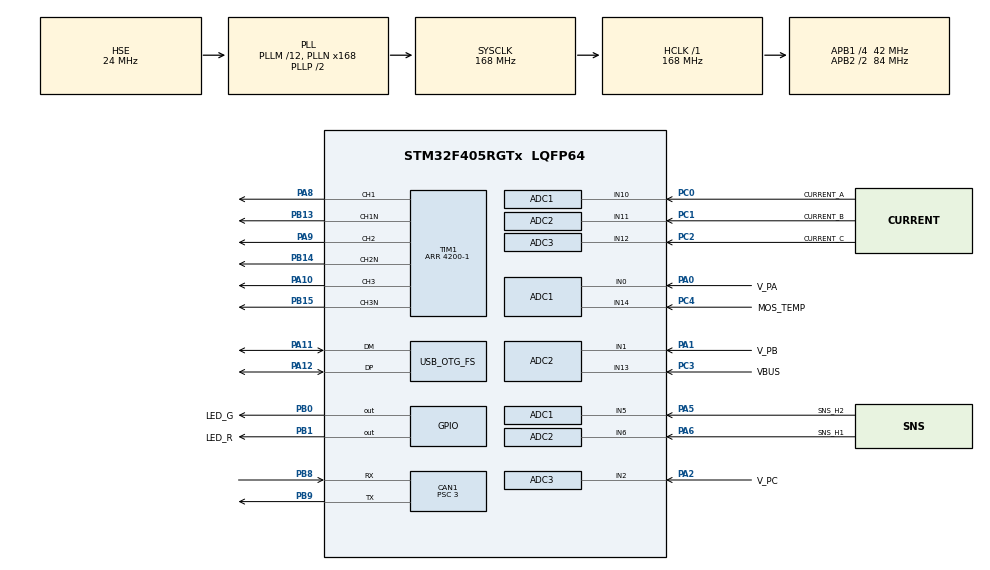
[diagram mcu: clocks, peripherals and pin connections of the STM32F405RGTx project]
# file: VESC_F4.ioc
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ADC1.Channel-0\#ChannelRegularConversion=ADC_CHANNEL_14
ADC1.Channel-1\#ChannelInjectedConversion=ADC_CHANNEL_10
ADC1.Channel-5\#ChannelInjectedConversion=ADC_CHANNEL_0
ADC1.Channel-6\#ChannelInjectedConversion=ADC_CHANNEL_5
ADC1.ClockPrescaler=ADC_CLOCK_SYNC_PCLK_DIV4
ADC1.ExternalTrigConv=ADC_EXTERNALTRIGCONV_T2_TRGO
ADC1.ExternalTrigInjecConv=ADC_EXTERNALTRIGINJECCONV_T1_TRGO
ADC1.InjNumberOfConversion=3
ADC1.InjectedOffset-1\#ChannelInjectedConversion=0
ADC1.InjectedOffset-5\#ChannelInjectedConversion=0
ADC1.InjectedOffset-6\#ChannelInjectedConversion=0
ADC1.InjectedRank-1\#ChannelInjectedConversion=1
ADC1.InjectedRank-5\#ChannelInjectedConversion=2
ADC1.InjectedRank-6\#ChannelInjectedConversion=3
ADC1.NbrOfConversion=1
ADC1.NbrOfConversionFlag=1
ADC1.Rank-0\#ChannelRegularConversion=1
ADC1.SamplingTime-0\#ChannelRegularConversion=ADC_SAMPLETIME_480CYCLES
ADC1.SamplingTime-1\#ChannelInjectedConversion=ADC_SAMPLETIME_15CYCLES
ADC1.SamplingTime-5\#ChannelInjectedConversion=ADC_SAMPLETIME_112CYCLES
ADC1.SamplingTime-6\#ChannelInjectedConversion=ADC_SAMPLETIME_28CYCLES
ADC1.master=1
ADC2.Channel-0\#ChannelRegularConversion=ADC_CHANNEL_13
ADC2.Channel-1\#ChannelInjectedConversion=ADC_CHANNEL_11
ADC2.Channel-4\#ChannelInjectedConversion=ADC_CHANNEL_1
ADC2.Channel-5\#ChannelInjectedConversion=ADC_CHANNEL_6
ADC2.ClockPrescaler=ADC_CLOCK_SYNC_PCLK_DIV4
ADC2.EnableAnalogWatchDog=false
ADC2.ExternalTrigConv=ADC_EXTERNALTRIGCONV_T2_TRGO
ADC2.ExternalTrigInjecConv=ADC_EXTERNALTRIGINJECCONV_T1_TRGO
ADC2.InjNumberOfConversion=3
ADC2.InjectedOffset-1\#ChannelInjectedConversion=0
ADC2.InjectedOffset-4\#ChannelInjectedConversion=0
ADC2.InjectedOffset-5\#ChannelInjectedConversion=0
ADC2.InjectedRank-1\#ChannelInjectedConversion=1
ADC2.InjectedRank-4\#ChannelInjectedConversion=2
ADC2.InjectedRank-5\#ChannelInjectedConversion=3
ADC2.NbrOfConversion=1
ADC2.NbrOfConversionFlag=1
ADC2.Rank-0\#ChannelRegularConversion=1
ADC2.SamplingTime-0\#ChannelRegularConversion=ADC_SAMPLETIME_144CYCLES
ADC2.SamplingTime-1\#ChannelInjectedConversion=ADC_SAMPLETIME_15CYCLES
ADC2.SamplingTime-4\#ChannelInjectedConversion=ADC_SAMPLETIME_112CYCLES
ADC2.SamplingTime-5\#ChannelInjectedConversion=ADC_SAMPLETIME_28CYCLES
ADC3.Channel-2\#ChannelRegularConversion=ADC_CHANNEL_2
ADC3.Channel-3\#ChannelInjectedConversion=ADC_CHANNEL_12
ADC3.Channel-4\#ChannelInjectedConversion=ADC_CHANNEL_2
ADC3.ClockPrescaler=ADC_CLOCK_SYNC_PCLK_DIV4
ADC3.ExternalTrigInjecConv=ADC_EXTERNALTRIGINJECCONV_T1_TRGO
ADC3.InjNumberOfConversion=2
ADC3.InjectedOffset-3\#ChannelInjectedConversion=0
ADC3.InjectedOffset-4\#ChannelInjectedConversion=0
ADC3.InjectedRank-3\#ChannelInjectedConversion=1
ADC3.InjectedRank-4\#ChannelInjectedConversion=2
ADC3.NbrOfConversion=1
ADC3.NbrOfConversionFlag=1
ADC3.Rank-2\#ChannelRegularConversion=1
ADC3.SamplingTime-2\#ChannelRegularConversion=ADC_SAMPLETIME_112CYCLES
ADC3.SamplingTime-3\#ChannelInjectedConversion=ADC_SAMPLETIME_15CYCLES
ADC3.SamplingTime-4\#ChannelInjectedConversion=ADC_SAMPLETIME_112CYCLES
CAN1.BS1=CAN_BS1_10TQ
CAN1.BS2=CAN_BS2_3TQ
CAN1.CalculateBaudRate=1000000
CAN1.CalculateTimeBit=1000
CAN1.CalculateTimeQuantum=71.42857142857143
CAN1.NART=ENABLE
CAN1.Prescaler=3
Mcu.Family=STM32F4
Mcu.Name=STM32F405RGTx
Mcu.Package=LQFP64
NVIC.ADC_IRQn=true\:0\:0\:false\:false\:true\:true\:true\:true
NVIC.CAN1_RX0_IRQn=true\:2\:0\:true\:false\:true\:true\:true\:true
NVIC.OTG_FS_IRQn=true\:3\:0\:true\:false\:true\:false\:true\:true
NVIC.PriorityGroup=NVIC_PRIORITYGROUP_4
NVIC.TIM1_UP_TIM10_IRQn=true\:0\:0\:false\:false\:true\:true\:true\:true
NVIC.TIM2_IRQn=true\:1\:0\:true\:false\:true\:true\:true\:true
PA0-WKUP.GPIO_Label=V_PA
PA0-WKUP.Signal=ADCx_IN0
PA1.GPIO_Label=V_PB
PA1.Signal=ADCx_IN1
PA10.Signal=S_TIM1_CH3
PA11.Mode=Device_Only
PA11.Signal=USB_OTG_FS_DM
PA12.Mode=Device_Only
PA12.Signal=USB_OTG_FS_DP
PA13.Mode=Serial_Wire
PA13.Signal=SYS_JTMS-SWDIO
PA14.Mode=Serial_Wire
PA14.Signal=SYS_JTCK-SWCLK
PA2.GPIO_Label=V_PC
PA2.Signal=ADCx_IN2
PA5.GPIO_Label=SNS_H2
PA5.Signal=ADCx_IN5
PA6.GPIO_Label=SNS_H1
PA6.Signal=ADCx_IN6
PA8.Signal=S_TIM1_CH1
PA9.Signal=S_TIM1_CH2
PB0.GPIO_Label=LED_G
PB0.PinState=GPIO_PIN_SET
PB0.Signal=GPIO_Output
PB1.GPIO_Label=LED_R
PB1.PinState=GPIO_PIN_SET
PB1.Signal=GPIO_Output
PB13.Mode=PWM Generation1 CH1 CH1N
PB13.Signal=TIM1_CH1N
PB14.Mode=PWM Generation2 CH2 CH2N
PB14.Signal=TIM1_CH2N
PB15.Mode=PWM Generation3 CH3 CH3N
PB15.Signal=TIM1_CH3N
PB8.Mode=CAN_Activate
PB8.Signal=CAN1_RX
PB9.Mode=CAN_Activate
PB9.Signal=CAN1_TX
PC0.GPIO_Label=CURRENT_A
PC0.Signal=ADCx_IN10
PC1.GPIO_Label=CURRENT_B
PC1.Signal=ADCx_IN11
PC2.GPIO_Label=CURRENT_C
PC2.Signal=ADCx_IN12
PC3.GPIO_Label=VBUS
PC3.Signal=ADCx_IN13
PC4.GPIO_Label=MOS_TEMP
PC4.Signal=ADCx_IN14
PH0-OSC_IN.Mode=HSE-External-Oscillator
PH0-OSC_IN.Signal=RCC_OSC_IN
PH1-OSC_OUT.Mode=HSE-External-Oscillator
PH1-OSC_OUT.Signal=RCC_OSC_OUT
ProjectManager.HeapSize=0x200
ProjectManager.StackSize=0x400
ProjectManager.TargetToolchain=CMake
RCC.48MHZClocksFreq_Value=48000000
RCC.AHBFreq_Value=168000000
RCC.APB1CLKDivider=RCC_HCLK_DIV4
RCC.APB1Freq_Value=42000000
RCC.APB1TimFreq_Value=84000000
RCC.APB2CLKDivider=RCC_HCLK_DIV2
RCC.APB2Freq_Value=84000000
RCC.APB2TimFreq_Value=168000000
RCC.CortexFreq_Value=168000000
RCC.HCLKFreq_Value=168000000
RCC.HSE_VALUE=24000000
RCC.HSI_VALUE=16000000
RCC.LSE_VALUE=32768
RCC.PLLM=12
RCC.PLLN=168
RCC.PLLQ=7
RCC.SYSCLKFreq_VALUE=168000000
RCC.SYSCLKSource=RCC_SYSCLKSOURCE_PLLCLK
RCC.VCOOutputFreq_Value=336000000
SH.ADCx_IN0.0=ADC1_IN0,IN0
SH.ADCx_IN1.0=ADC2_IN1,IN1
SH.ADCx_IN10.0=ADC1_IN10,IN10
SH.ADCx_IN11.0=ADC2_IN11,IN11
SH.ADCx_IN12.0=ADC3_IN12,IN12
SH.ADCx_IN13.0=ADC2_IN13,IN13
SH.ADCx_IN14.0=ADC1_IN14,IN14
SH.ADCx_IN2.0=ADC3_IN2,IN2
SH.ADCx_IN5.0=ADC1_IN5,IN5
SH.ADCx_IN6.0=ADC2_IN6,IN6
SH.S_TIM1_CH1.0=TIM1_CH1,PWM Generation1 CH1 CH1N
SH.S_TIM1_CH2.0=TIM1_CH2,PWM Generation2 CH2 CH2N
SH.S_TIM1_CH3.0=TIM1_CH3,PWM Generation3 CH3 CH3N
TIM1.Channel-PWM\ Generation1\ CH1\ CH1N=TIM_CHANNEL_1
TIM1.Channel-PWM\ Generation2\ CH2\ CH2N=TIM_CHANNEL_2
TIM1.Channel-PWM\ Generation3\ CH3\ CH3N=TIM_CHANNEL_3
TIM1.CounterMode=TIM_COUNTERMODE_CENTERALIGNED1
TIM1.DeadTime=20
TIM1.OCMode_PWM-PWM\ Generation1\ CH1\ CH1N=TIM_OCMODE_PWM2
TIM1.OCMode_PWM-PWM\ Generation2\ CH2\ CH2N=TIM_OCMODE_PWM2
TIM1.OCMode_PWM-PWM\ Generation3\ CH3\ CH3N=TIM_OCMODE_PWM2
TIM1.OffStateIDLEMode=TIM_OSSI_ENABLE
TIM1.OffStateRunMode=TIM_OSSR_ENABLE
TIM1.Period=4200-1
TIM1.Pulse-PWM\ Generation1\ CH1\ CH1N=2100
TIM1.Pulse-PWM\ Generation2\ CH2\ CH2N=2100
TIM1.Pulse-PWM\ Generation3\ CH3\ CH3N=2100
TIM1.RepetitionCounter=1
TIM1.TIM_MasterOutputTrigger=TIM_TRGO_UPDATE
TIM2.Period=1000-1
TIM2.Prescaler=84-1
TIM2.TIM_MasterOutputTrigger=TIM_TRGO_UPDATE
USB_DEVICE.CLASS_NAME_FS=CDC
USB_DEVICE.PRODUCT_STRING_CDC_FS=F4Driver
USB_DEVICE.VirtualMode-CDC_FS=Cdc
USB_DEVICE.VirtualModeFS=Cdc_FS
USB_OTG_FS.VirtualMode=Device_Only
VP_TIM1_VS_ClockSourceINT.Mode=Internal
VP_TIM2_VS_ClockSourceINT.Mode=Internal
VP_USB_DEVICE_VS_USB_DEVICE_CDC_FS.Mode=CDC_FS
board=custom

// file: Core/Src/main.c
/* USER CODE BEGIN Header */
/**
  ******************************************************************************
  * @file           : main.c
  * @brief          : Main program body
  ******************************************************************************
  * @attention
  *
  * Copyright (c) 2026 STMicroelectronics.
  * All rights reserved.
  *
  * This software is licensed under terms that can be found in the LICENSE file
  * in the root directory of this software component.
  * If no LICENSE file comes with this software, it is provided AS-IS.
  *
  ******************************************************************************
  */
/* USER CODE END Header */
#include "main.h"
#include "adc.h"
#include "can.h"
#include "tim.h"
#include "usb_device.h"
#include "gpio.h"

/* USER CODE BEGIN Includes */
#include "BspCan.h"
#include "FocApp.h"
#include "FocComm.h"
#include "BspUsbVcp.h"
#include "BspBoot.h"
#include "ShellPort.h"
/* USER CODE END Includes */

/* USER CODE BEGIN PD */
extern BspCan_s Can1;
extern Foc_s Foc;
/* USER CODE END PD */

void SystemClock_Config(void);

int main(void)
{

  /* MCU Configuration--------------------------------------------------------*/

  /* Reset of all peripherals, Initializes the Flash interface and the Systick. */
  HAL_Init();

  /* Configure the system clock */
  SystemClock_Config();

  /* USER CODE BEGIN SysInit */
  BspUsbVcp_Init();
  ShellPort_Init();
  /* USER CODE END SysInit */

  /* Initialize all configured peripherals */
  MX_GPIO_Init();
  MX_ADC1_Init();
  MX_CAN1_Init();
  MX_TIM1_Init();
  MX_ADC2_Init();
  MX_TIM2_Init();
  MX_ADC3_Init();
  MX_USB_DEVICE_Init();
  /* USER CODE BEGIN 2 */
  FocApp_BspInit();
  /* USER CODE END 2 */

  /* Infinite loop */
  /* USER CODE BEGIN WHILE */
  while (1)
  {
    BspUsbVcp_Poll();
    BspBoot_Poll();
    HAL_Delay(1);
    /* USER CODE END WHILE */

  }
}

void SystemClock_Config(void)
{
  RCC_OscInitTypeDef RCC_OscInitStruct = {0};
  RCC_ClkInitTypeDef RCC_ClkInitStruct = {0};

  /** Configure the main internal regulator output voltage
  */
  __HAL_RCC_PWR_CLK_ENABLE();
  __HAL_PWR_VOLTAGESCALING_CONFIG(PWR_REGULATOR_VOLTAGE_SCALE1);

  /** Initializes the RCC Oscillators according to the specified parameters
  * in the RCC_OscInitTypeDef structure.
  */
  RCC_OscInitStruct.OscillatorType = RCC_OSCILLATORTYPE_HSE;
  RCC_OscInitStruct.HSEState = RCC_HSE_ON;
  RCC_OscInitStruct.PLL.PLLState = RCC_PLL_ON;
  RCC_OscInitStruct.PLL.PLLSource = RCC_PLLSOURCE_HSE;
  RCC_OscInitStruct.PLL.PLLM = 12;
  RCC_OscInitStruct.PLL.PLLN = 168;
  RCC_OscInitStruct.PLL.PLLP = RCC_PLLP_DIV2;
  RCC_OscInitStruct.PLL.PLLQ = 7;
  if (HAL_RCC_OscConfig(&RCC_OscInitStruct) != HAL_OK)
  {
    Error_Handler();
  }

  /** Initializes the CPU, AHB and APB buses clocks
  */
  RCC_ClkInitStruct.ClockType = RCC_CLOCKTYPE_HCLK|RCC_CLOCKTYPE_SYSCLK
                              |RCC_CLOCKTYPE_PCLK1|RCC_CLOCKTYPE_PCLK2;
  RCC_ClkInitStruct.SYSCLKSource = RCC_SYSCLKSOURCE_PLLCLK;
  RCC_ClkInitStruct.AHBCLKDivider = RCC_SYSCLK_DIV1;
  RCC_ClkInitStruct.APB1CLKDivider = RCC_HCLK_DIV4;
  RCC_ClkInitStruct.APB2CLKDivider = RCC_HCLK_DIV2;

  if (HAL_RCC_ClockConfig(&RCC_ClkInitStruct, FLASH_LATENCY_5) != HAL_OK)
  {
    Error_Handler();
  }
}

void Error_Handler(void)
{
  __disable_irq();
  while (1)
  {
  }
}
